# STM32H5xx register map
File version: 0.3
CPU: CM33 r0p0, little endian, MPU, FPU, 4 interrupt priority bits
Registers are 32-bit, read-write, reset 0x0 unless marked. A register's access mark holds for its fields unless they carry their own. Offsets are from the block's base; [hi:lo] are bit positions; {n}, {i} and the like mark numbered series.

## CORDIC — CORDIC Co-processor
Base 0x40021000
Same registers: SEC_CORDIC 0x50021000
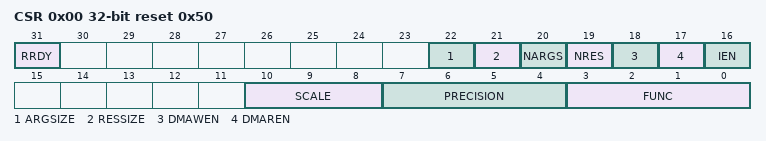
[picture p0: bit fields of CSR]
0x00 CSR access per field reset 0x50 — CORDIC Control Status register
  [31] RRDY ro — Result ready flag
  [22] ARGSIZE rw — Width of input data
  [21] RESSIZE rw — Width of output data
  [20] NARGS rw — Number of arguments expected by the CORDIC_WDATA register
  [19] NRES rw — Number of results in the CORDIC_RDATA register
  [18] DMAWEN rw — Enable DMA write channel
  [17] DMAREN rw — Enable DMA read channel
  [16] IEN rw — Enable interrupt
  [10:8] SCALE rw — Scaling factor
  [7:4] PRECISION rw — Precision required (number of iterations)
  [3:0] FUNC rw — Function
0x04 WDATA wo — FMAC Write Data register
  [31:0] ARG — Function input arguments
0x08 RDATA ro — FMAC Read Data register
  [31:0] RES — Function result

## FMAC — Filter Math Accelerator
Base 0x40021400
Same registers: SEC_FMAC 0x50021400
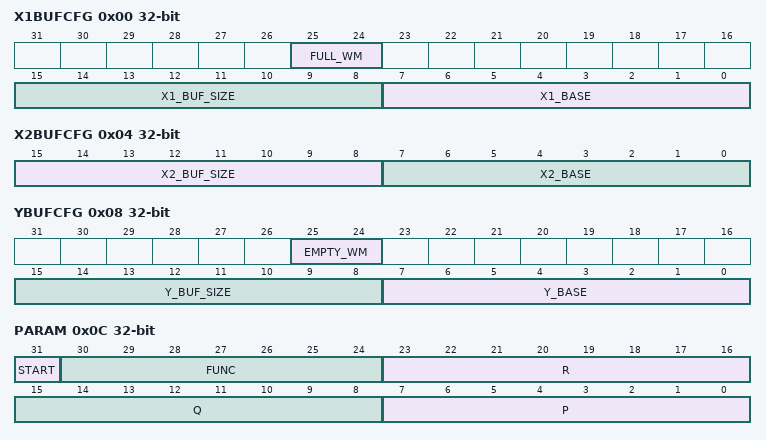
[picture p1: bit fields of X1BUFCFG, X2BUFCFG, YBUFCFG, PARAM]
0x00 X1BUFCFG — FMAC X1 Buffer Configuration register
  [25:24] FULL_WM — Watermark for buffer full flag
  [15:8] X1_BUF_SIZE — Allocated size of X1 buffer in 16-bit words
  [7:0] X1_BASE — Base address of X1 buffer
0x04 X2BUFCFG — FMAC X2 Buffer Configuration register
  [15:8] X2_BUF_SIZE — Size of X2 buffer in 16-bit words
  [7:0] X2_BASE — Base address of X2 buffer
0x08 YBUFCFG — FMAC Y Buffer Configuration register
  [25:24] EMPTY_WM — Watermark for buffer empty flag
  [15:8] Y_BUF_SIZE — Size of Y buffer in 16-bit words
  [7:0] Y_BASE — Base address of Y buffer
0x0C PARAM — FMAC Parameter register
  [31] START — Enable execution
  [30:24] FUNC — Function
  [23:16] R — Input parameter R
  [15:8] Q — Input parameter Q
  [7:0] P — Input parameter P
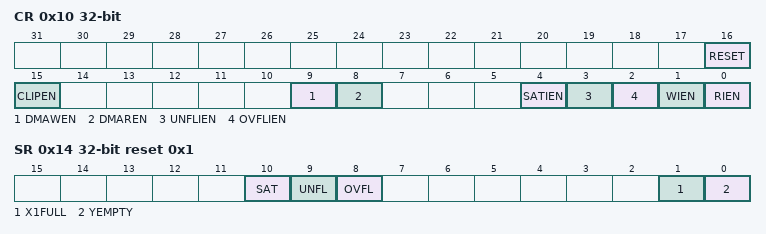
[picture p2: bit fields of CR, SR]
0x10 CR — FMAC Control register
  [16] RESET — Reset FMAC unit
  [15] CLIPEN — Enable clipping
  [9] DMAWEN — Enable DMA write channel requests
  [8] DMAREN — Enable DMA read channel requests
  [4] SATIEN — Enable saturation error interrupts
  [3] UNFLIEN — Enable underflow error interrupts
  [2] OVFLIEN — Enable overflow error interrupts
  [1] WIEN — Enable write interrupt
  [0] RIEN — Enable read interrupt
0x14 SR ro reset 0x1 — FMAC Status register
  [10] SAT — Saturation error flag
  [9] UNFL — Underflow error flag
  [8] OVFL — Overflow error flag
  [1] X1FULL — X1 buffer full flag
  [0] YEMPTY — Y buffer empty flag
0x18 WDATA wo — FMAC Write Data register
  [15:0] WDATA — Write data
0x1C RDATA ro — FMAC Read Data register
  [15:0] RDATA — Read data

## GPIOA — General-purpose I/Os
Base 0x42020000
Same registers: SEC_GPIOA 0x52020000
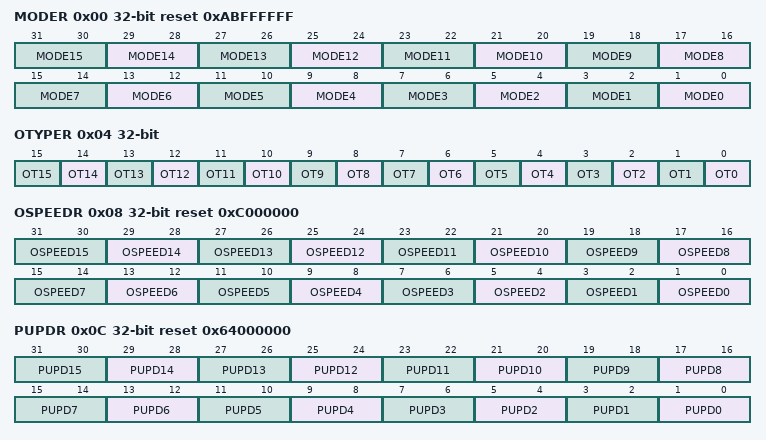
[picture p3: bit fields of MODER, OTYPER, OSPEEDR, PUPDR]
0x00 MODER reset 0xABFFFFFF — GPIO port mode register
  [2n+1:2n] MODE{n} (n=0..15) — Port x configuration bits (y = 0..15)
0x04 OTYPER — GPIO port output type register
  [n] OT{n} (n=0..15) — Port x configuration bits (y = 0..15)
0x08 OSPEEDR reset 0xC000000 — GPIO port output speed register
  [2n+1:2n] OSPEED{n} (n=0..15) — Port x configuration bits (y = 0..15)
0x0C PUPDR reset 0x64000000 — GPIO port pull-up/pull-down register
  [2n+1:2n] PUPD{n} (n=0..15) — Port x configuration bits (y = 0..15)
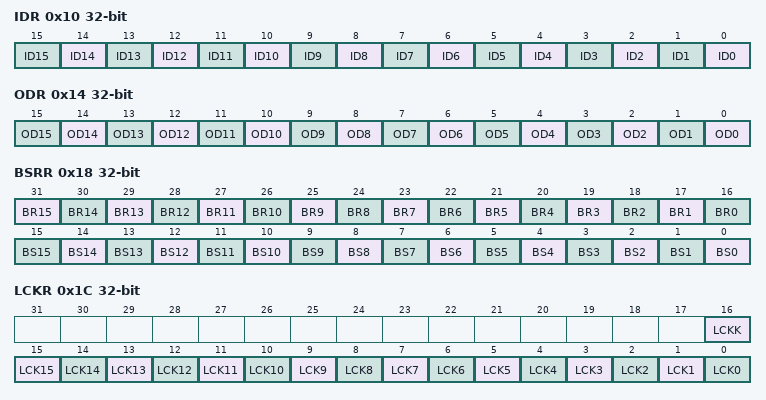
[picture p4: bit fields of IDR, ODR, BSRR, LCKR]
0x10 IDR ro — GPIO port input data register
  [n] ID{n} (n=0..15) — Port input data (y = 0..15)
0x14 ODR — GPIO port output data register
  [n] OD{n} (n=0..15) — Port output data (y = 0..15)
0x18 BSRR wo — GPIO port bit set/reset register
  [n+16] BR{n} (n=1..15) — Port x reset bit y (y = 0..15)
  [16] BR0 — Port x set bit y (y= 0..15)
  [n] BS{n} (n=0..15) — Port x set bit y (y= 0..15)
0x1C LCKR — GPIO port configuration lock register
  [16] LCKK — Lock key
  [n] LCK{n} (n=0..15) — Port x lock bit y (y= 0..15)
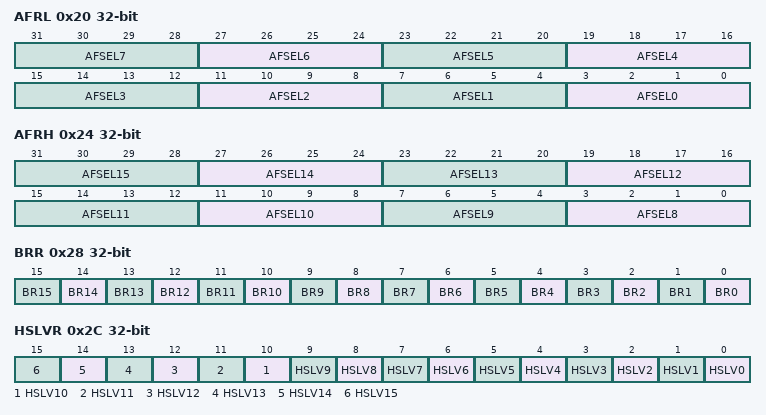
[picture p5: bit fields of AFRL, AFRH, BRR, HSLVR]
0x20 AFRL — GPIO alternate function low register
  [4n+3:4n] AFSEL{n} (n=0..7) — Alternate function selection for port x bit y (y = 0..7)
0x24 AFRH — GPIO alternate function high register
  [4n-29:4n-32] AFSEL{n} (n=8..15) — Alternate function selection for port x bit y (y = 8..15)
0x28 BRR wo — GPIO port bit reset register
  [n] BR{n} (n=0..15) — Port x reset IO pin y
0x2C HSLVR — GPIO high-speed low-voltage register
  [n] HSLV{n} (n=0..15) — Port x high-speed low-voltage configuration (y= 15 to 0)
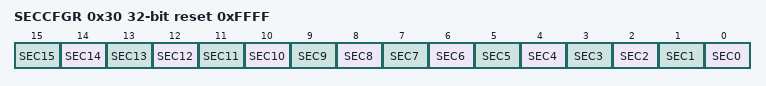
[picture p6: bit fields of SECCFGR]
0x30 SECCFGR wo reset 0xFFFF — GPIO secure configuration register
  [n] SEC{n} (n=0..15) — I/O pin of Port x secure bit enable

## GPIOB — General-purpose I/Os
Base 0x42020400
Same registers: SEC_GPIOB 0x52020400
Registers as GPIOA; these are added or differ:
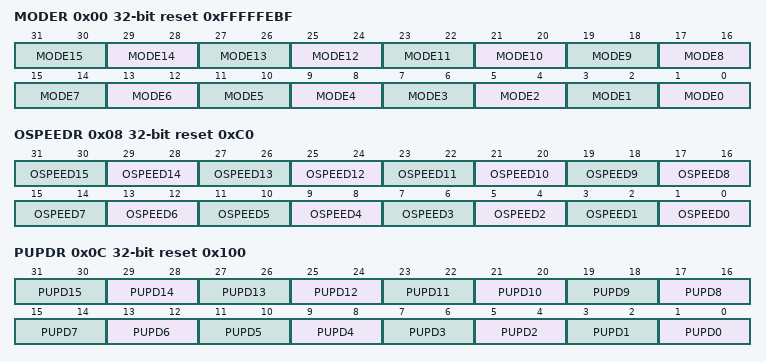
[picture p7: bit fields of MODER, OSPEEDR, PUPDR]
0x00 MODER reset 0xFFFFFEBF — GPIO port mode register
  [2n+1:2n] MODE{n} (n=0..15) — Port x configuration bits (y = 0..15)
0x08 OSPEEDR reset 0xC0 — GPIO port output speed register
  [2n+1:2n] OSPEED{n} (n=0..15) — Port x configuration bits (y = 0..15)
0x0C PUPDR reset 0x100 — GPIO port pull-up/pull-down register
  [2n+1:2n] PUPD{n} (n=0..15) — Port x configuration bits (y = 0..15)

## GPIOC — General-purpose I/Os
Base 0x42020800
Same registers: GPIOD 0x42020C00, GPIOE 0x42021000, GPIOF 0x42021400, GPIOG 0x42021800, GPIOH 0x42021C00, SEC_GPIOC 0x52020800, SEC_GPIOD 0x52020C00, SEC_GPIOE 0x52021000, SEC_GPIOF 0x52021400, SEC_GPIOG 0x52021800, SEC_GPIOH 0x52021C00
Registers as GPIOA; these are added or differ:
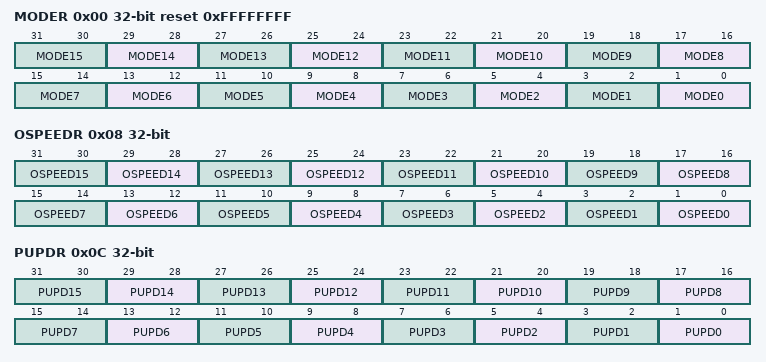
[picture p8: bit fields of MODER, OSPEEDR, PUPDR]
0x00 MODER reset 0xFFFFFFFF — GPIO port mode register
  [2n+1:2n] MODE{n} (n=0..15) — Port x configuration bits (y = 0..15)
0x08 OSPEEDR — GPIO port output speed register
  [2n+1:2n] OSPEED{n} (n=0..15) — Port x configuration bits (y = 0..15)
0x0C PUPDR — GPIO port pull-up/pull-down register
  [2n+1:2n] PUPD{n} (n=0..15) — Port x configuration bits (y = 0..15)

## Notices in the file
Copyright (c) 2021 STMicroelectronics.
SPDX-License-Identifier: Apache-2.0
Licensed under the Apache License, Version 2.0 (the "License");
you may not use this file except in compliance with the License.
You may obtain a copy of the License at
http://www.apache.org/licenses/LICENSE-2.0
Unless required by applicable law or agreed to in writing, software
distributed under the License is distributed on an "AS IS" BASIS,
WITHOUT WARRANTIES OR CONDITIONS OF ANY KIND, either express or implied.
See the License for the specific language governing permissions and
limitations under the License.
